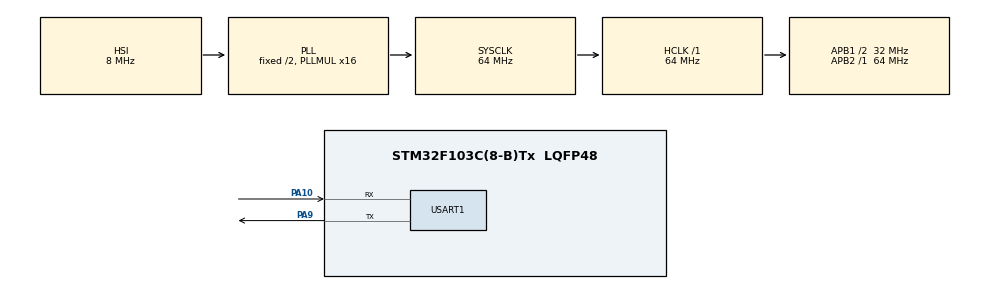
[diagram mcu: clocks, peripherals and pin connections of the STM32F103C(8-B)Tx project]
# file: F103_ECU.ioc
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Mcu.Family=STM32F1
Mcu.Name=STM32F103C(8-B)Tx
Mcu.Package=LQFP48
NVIC.PriorityGroup=NVIC_PRIORITYGROUP_4
PA10.Mode=Asynchronous
PA10.Signal=USART1_RX
PA13.Mode=Serial_Wire
PA13.Signal=SYS_JTMS-SWDIO
PA14.Mode=Serial_Wire
PA14.Signal=SYS_JTCK-SWCLK
PA9.Mode=Asynchronous
PA9.Signal=USART1_TX
ProjectManager.HeapSize=0x200
ProjectManager.StackSize=0x400
ProjectManager.TargetToolchain=CMake
RCC.AHBFreq_Value=64000000
RCC.APB1CLKDivider=RCC_HCLK_DIV2
RCC.APB1Freq_Value=32000000
RCC.APB1TimFreq_Value=64000000
RCC.APB2Freq_Value=64000000
RCC.APB2TimFreq_Value=64000000
RCC.HCLKFreq_Value=64000000
RCC.PLLMUL=RCC_PLL_MUL16
RCC.SYSCLKFreq_VALUE=64000000
RCC.SYSCLKSource=RCC_SYSCLKSOURCE_PLLCLK
RCC.USBFreq_Value=64000000
USART1.VirtualMode=VM_ASYNC
board=custom

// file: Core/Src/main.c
/* USER CODE BEGIN Header */
/**
  ******************************************************************************
  * @file           : main.c
  * @brief          : Main program body
  ******************************************************************************
  * @attention
  *
  * Copyright (c) 2026 STMicroelectronics.
  * All rights reserved.
  *
  * This software is licensed under terms that can be found in the LICENSE file
  * in the root directory of this software component.
  * If no LICENSE file comes with this software, it is provided AS-IS.
  *
  ******************************************************************************
  */
/* USER CODE END Header */
#include "main.h"
#include "usart.h"
#include "gpio.h"

/* USER CODE BEGIN Includes */
#include "Can.h"
#include "isotp.h"
#include "UDS.h"
/* USER CODE END Includes */

void SystemClock_Config(void);
/* USER CODE BEGIN PFP */
static uint8_t Boot_IsAppValid(void);
static void Boot_JumpToApp(void);
/* USER CODE END PFP */

/* USER CODE BEGIN 0 */
uint8_t RXData[1024];
CAN_TxHeaderTypeDef TXHeader={0x7E8,0,CAN_ID_STD,CAN_RTR_DATA,8,DISABLE};
CAN_RxHeaderTypeDef CAN_RxHeader;
uint32_t pTxMailbox;
uint32_t pRxMailbox;
uint8_t SN;

#define APP_START_ADDRESS 0x08008000U

__attribute__((naked,noreturn)) static void Boot_StartApp(uint32_t AppStack,uint32_t AppResetHandler)
{
  __asm volatile(
    "msr msp,r0\n"
    "cpsie i\n"
    "bx r1\n"
  );
}

static uint8_t Boot_IsAppValid(void)
{
  uint32_t AppStack=*(uint32_t *)APP_START_ADDRESS;
  uint32_t AppResetHandler=*(uint32_t *)(APP_START_ADDRESS+4U);
  if ((AppStack<0x20000000U)||(AppStack>0x20005000U))
  {
    return 0;
  }
  if ((AppResetHandler<APP_START_ADDRESS)||(AppResetHandler>=0x08010000U))
  {
    return 0;
  }
  return 1;
}

static void Boot_JumpToApp(void)
{
  uint32_t AppStack=*(uint32_t *)APP_START_ADDRESS;
  uint32_t AppResetHandler=*(uint32_t *)(APP_START_ADDRESS+4U);

  if (Boot_IsAppValid()==0)
  {
    return;
  }

  HAL_CAN_Stop(&hcan1);
  HAL_RCC_DeInit();
  HAL_DeInit();

  __disable_irq();

  SysTick->CTRL=0;
  SysTick->LOAD=0;
  SysTick->VAL=0;

  SCB->ICSR=SCB_ICSR_PENDSTCLR_Msk|SCB_ICSR_PENDSVCLR_Msk;

  NVIC->ICER[0]=0xFFFFFFFFU;
  NVIC->ICER[1]=0xFFFFFFFFU;
  NVIC->ICPR[0]=0xFFFFFFFFU;
  NVIC->ICPR[1]=0xFFFFFFFFU;

  SCB->VTOR=APP_START_ADDRESS;
  __DSB();
  __ISB();
  Boot_StartApp(AppStack,AppResetHandler);
}
/* USER CODE END 0 */

int main(void)
{

  /* MCU Configuration--------------------------------------------------------*/

  /* Reset of all peripherals, Initializes the Flash interface and the Systick. */
  HAL_Init();

  /* Configure the system clock */
  SystemClock_Config();

  /* Initialize all configured peripherals */
  MX_GPIO_Init();
  MX_USART1_UART_Init();
  /* USER CODE BEGIN 2 */

  UDS_Init();

  /* USER CODE END 2 */
  /* Infinite loop */
  /* USER CODE BEGIN WHILE */
  while (1)
  {
    UDS_Divide_ID(RXData);
    if (AppJumpRequested==1)
    {
      HAL_Delay(100);
      Boot_JumpToApp();
    }
  }
  /* USER CODE END 3 */
}

void SystemClock_Config(void)
{
  RCC_OscInitTypeDef RCC_OscInitStruct = {0};
  RCC_ClkInitTypeDef RCC_ClkInitStruct = {0};

  /** Initializes the RCC Oscillators according to the specified parameters
  * in the RCC_OscInitTypeDef structure.
  */
  RCC_OscInitStruct.OscillatorType = RCC_OSCILLATORTYPE_HSI;
  RCC_OscInitStruct.HSIState = RCC_HSI_ON;
  RCC_OscInitStruct.HSICalibrationValue = RCC_HSICALIBRATION_DEFAULT;
  RCC_OscInitStruct.PLL.PLLState = RCC_PLL_ON;
  RCC_OscInitStruct.PLL.PLLSource = RCC_PLLSOURCE_HSI_DIV2;
  RCC_OscInitStruct.PLL.PLLMUL = RCC_PLL_MUL16;
  if (HAL_RCC_OscConfig(&RCC_OscInitStruct) != HAL_OK)
  {
    Error_Handler();
  }

  /** Initializes the CPU, AHB and APB buses clocks
  */
  RCC_ClkInitStruct.ClockType = RCC_CLOCKTYPE_HCLK|RCC_CLOCKTYPE_SYSCLK
                              |RCC_CLOCKTYPE_PCLK1|RCC_CLOCKTYPE_PCLK2;
  RCC_ClkInitStruct.SYSCLKSource = RCC_SYSCLKSOURCE_PLLCLK;
  RCC_ClkInitStruct.AHBCLKDivider = RCC_SYSCLK_DIV1;
  RCC_ClkInitStruct.APB1CLKDivider = RCC_HCLK_DIV2;
  RCC_ClkInitStruct.APB2CLKDivider = RCC_HCLK_DIV1;

  if (HAL_RCC_ClockConfig(&RCC_ClkInitStruct, FLASH_LATENCY_2) != HAL_OK)
  {
    Error_Handler();
  }
}

void Error_Handler(void)
{
  __disable_irq();
  while (1)
  {
  }
}
